# M3351 register map
File version: 1.0
Registers are 32-bit, read-write, reset 0x0 unless marked. A register's access mark holds for its fields unless they carry their own. Offsets are from the block's base; [hi:lo] are bit positions; {n}, {i} and the like mark numbered series; 'fields as' and 'values as' point back to an identical list.

## CLK (part 1 of 2) — CLK Register Map
Base 0x40000200
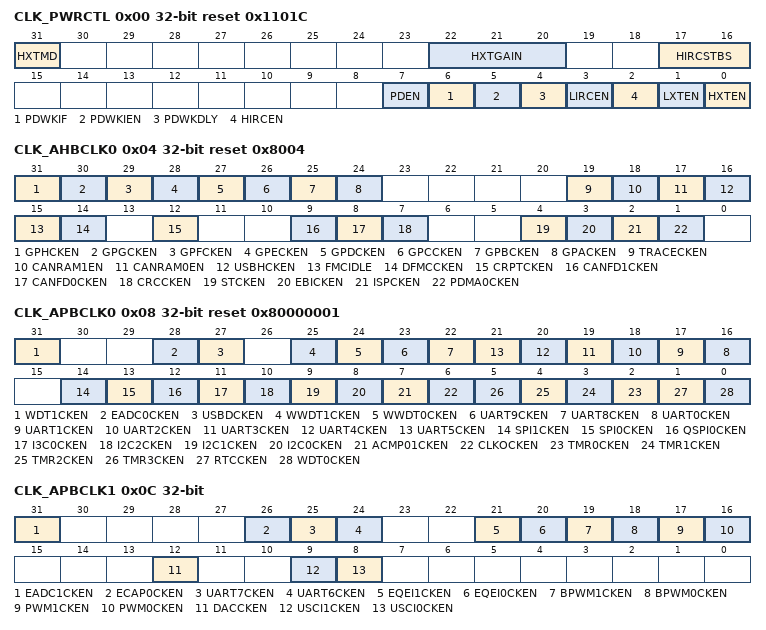
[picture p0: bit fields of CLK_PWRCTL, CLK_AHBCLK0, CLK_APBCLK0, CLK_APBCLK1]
0x00 CLK_PWRCTL reset 0x1101C (reset mask 0xFF0FFFFF) — System Power-down Control Register
  [31] HXTMD — HXT Mode Selection (Write Protect). Note: This bit is write protected. Refer to the SYS_REGCTL register.
    0=HXT work as crystal mode. PF.2 and PF.3 are configured as external high speed crystal (HXT) pins; 1=HXT works as external clock mode. PF.3 is configured as external clock input pin
  [22:20] HXTGAIN — HXT Gain Control Bit (Write Protect). Gain control is used to enlarge the gain of crystal to make sure crystal work normally. If gain control is enabled, crystal will consume more power than gain control off. Note: These bits are write protected. Refer to the SYS_REGLCTL register.
    0=HXT frequency is from 1 MHz to 4 MHz. (ESR=45ohm ; CLFXT =12.5pF); 1=HXT frequency is from 4 MHz to 8 MHz. (ESR=15ohm ; CLFXT =12.5pF); 2=HXT frequency is from 8 MHz to 12 MHz. (ESR=10ohm ; CLFXT =12.5pF); 3=HXT frequency is from 12 MHz to 16 MHz. (ESR=8.8ohm ; CLFXT =12.5pF); 4=HXT frequency is from 16 MHz to 24 MHz. (ESR=7.5ohm ; CLFXT =12.5pF); 5=HXT frequency is from 24 MHz to 32 MHz. (ESR=7.5ohm ; CLFXT =12.5pF)
  [17:16] HIRCSTBS — HIRC Stable Count Select (Write Protect). Note: These bits are write protected. Refer to the SYS_REGLCTL register.
    0=HIRC stable count is 1024 clocks; 1=HIRC stable count is 512 clocks
  [7] PDEN — System Power-down Enable (Write Protect). When this bit is set to 1, Power-down mode is enabled and chip keeps active till the CPU sleep mode is also active and then the chip enters Power-down mode. When chip wakes up from Power-down mode, this bit is auto cleared. Users need to set this bit again for next Power-down. In Power-down mode, HXT and the HIRC will be disabled in this mode, but LXT and LIRC are not controlled by Power-down mode. In Power-down mode, the PLL and system clock are disabled, and ignored the clock source selection. The clocks of peripheral are not controlled by Power-down mode, if the peripheral clock source is from LXT or LIRC. Note 1: This bit is write protected. Refer to the SYS_REGLCTL register. Note 2: System tick interrupt TICKINT(SYS_CTRL[1]) has to be disabled before entering to Power-down mode, to avoid system tick interrupt may influence system not entering power-down mode and keep operation.
    0=Chip will not enter Power-down mode after CPU sleep command WFI; 1=Chip enters Power-down mode after CPU sleep command WFI
  [6] PDWKIF — Power-down Mode Wake-up Interrupt Status. Set by 'Power-down wake-up event', it indicates that resume from Power-down mode. The flag is set if any wake-up source occurred. Refer Power Modes and Wake-up Sources chapter. Note 1: Write 1 to clear the bit to 0. Note 2: This bit works only if PDWKIEN (CLK_PWRCTL[5]) set to 1.
  [5] PDWKIEN — Power-down Mode Wake-up Interrupt Enable Bit (Write Protect). Note 1: The interrupt will occur when both PDWKIF and PDWKIEN are high. Note 2: This bit is write protected. Refer to the SYS_REGLCTL register.
    0=Power-down mode wake-up interrupt Disabled; 1=Power-down mode wake-up interrupt Enabled
  [4] PDWKDLY — Enable the Wake-up Delay Counter (Write Protect). When the chip wakes up from Power-down mode, the clock control will delay certain clock cycles to wait system clock stable. The delayed clock cycle is 1024 clock cycles when chip works using HXT, and 256 or 128 clock cycles when chip works using HIRC. Note: This bit is write protected. Refer to the SYS_REGLCTL register.
    0=Clock cycles delay Disabled; 1=Clock cycles delay Enabled
  [3] LIRCEN — LIRC Enable Bit (Write Protect). Note: This bit is write protected. Refer to the SYS_REGLCTL register.
    0=LIRC Disabled; 1=LIRC Enabled
  [2] HIRCEN — HIRC Enable Bit (Write Protect). Note 1: This bit is write protected. Refer to the SYS_REGLCTL register. Note 2: HIRC cannot be disabled and HIRCEN will read as 1 if HCLK clock source is selected from HIRC or PLL (clock source from HIRC).
    0=HIRC Disabled; 1=HIRC Enabled
  [1] LXTEN — LXT Enable Bit (Write Protect). Note: This bit is write protected. Refer to the SYS_REGLCTL register.
    0=LXT Disabled; 1=LXT Enabled
  [0] HXTEN — HXT Enable Bit (Write Protect). Note 1: This bit is write protected. Refer to the SYS_REGLCTL register. Note 2: HXT cannot be disabled and HXTEN will read as 1 if HCLK clock source is selected from HXT or PLL (clock source from HXT).
    0=HXT Disabled; 1=HXT Enabled
0x04 CLK_AHBCLK0 reset 0x8004 — AHB Devices Clock Enable Control Register 0
  [31] GPHCKEN — GPIOH Clock Enable Bit
    0=GPIOH clock Disabled; 1=GPIOH clock Enabled
  [30] GPGCKEN — GPIOG Clock Enable Bit
    0=GPIOG clock Disabled; 1=GPIOG clock Enabled
  [29] GPFCKEN — GPIOF Clock Enable Bit
    0=GPIOF clock Disabled; 1=GPIOF clock Enabled
  [28] GPECKEN — GPIOE Clock Enable Bit
    0=GPIOE clock Disabled; 1=GPIOE clock Enabled
  [27] GPDCKEN — GPIOD Clock Enable Bit
    0=GPIOD clock Disabled; 1=GPIOD clock Enabled
  [26] GPCCKEN — GPIOC Clock Enable Bit
    0=GPIOC clock Disabled; 1=GPIOC clock Enabled
  [25] GPBCKEN — GPIOB Clock Enable Bit
    0=GPIOB clock Disabled; 1=GPIOB clock Enabled
  [24] GPACKEN — GPIOA Clock Enable Bit
    0=GPIOA clock Disabled; 1=GPIOA clock Enabled
  [19] TRACECKEN — TRACE Clock Enable Bit
    0=TRACE clock Disabled; 1=TRACE clock Enabled
  [18] CANRAM1EN — CANFD1 Message SRAM Clock Enable Bit
    0=CANFD1 Message SRAM clock Disabled; 1=CANFD1 Message SRAM clock Enabled
  [17] CANRAM0EN — CANFD0 Message SRAM Clock Enable Bit
    0=CANFD0 Message SRAM clock Disabled; 1=CANFD0 Message SRAM clock Enabled
  [16] USBHCKEN — USB HOST Controller Clock Enable Bit
    0=USB HOST peripheral clock Disabled; 1=USB HOST peripheral clock Enabled
  [15] FMCIDLE — Flash Memory Controller Clock Enable Bit in IDLE Mode
    0=FMC clock Disabled when chip is under IDLE mode; 1=FMC clock Enabled when chip is under IDLE mode
  [14] DFMCCKEN — DFMC Clock Enable Bit
    0=DFMC clock Disabled; 1=DFMC clock Enabled
  [12] CRPTCKEN — Cryptographic Accelerator Clock Enable Bit
    0=Cryptographic Accelerator clock Disabled; 1=Cryptographic Accelerator clock Enabled
  [9] CANFD1CKEN — CANFD1 Clock Enable Bit
    0=CANFD1 clock Disabled; 1=CANFD1 clock Enabled
  [8] CANFD0CKEN — CANFD0 Clock Enable Bit
    0=CANFD0 clock Disabled; 1=CANFD0 clock Enabled
  [7] CRCCKEN — CRC Generator Controller Clock Enable Bit
    0=CRC peripheral clock Disabled; 1=CRC peripheral clock Enabled
  [4] STCKEN — System Tick Clock Enable Bit
    0=System tick clock Disabled; 1=System tick clock Enabled
  [3] EBICKEN — EBI Controller Clock Enable Bit
    0=EBI peripheral clock Disabled; 1=EBI peripheral clock Enabled
  [2] ISPCKEN — Flash ISP Controller Clock Enable Bit
    0=Flash ISP peripheral clock Disabled; 1=Flash ISP peripheral clock Enabled
  [1] PDMA0CKEN — PDMA0 Controller Clock Enable Bit
    0=PDMA0 peripheral clock Disabled; 1=PDMA0 peripheral clock Enabled
0x08 CLK_APBCLK0 reset 0x80000001 — APB Devices Clock Enable Control Register 0
  [31] WDT1CKEN — Watchdog Timer 1 Clock Enable Bit (Write Protect). Note: This bit is write protected. Refer to the SYS_REGLCTL register.
    0=Watchdog timer 1 clock Disabled; 1=Watchdog timer 1 clock Enabled
  [28] EADC0CKEN — EADC0 Clock Enable Bit
    0=EADC0 clock Disabled; 1=EADC0 clock Enabled
  [27] USBDCKEN — USB Device Clock Enable Bit
    0=USB device clock Disabled; 1=USB device clock Enabled
  [25] WWDT1CKEN — Window Watchdog Timer 1 Clock Enable Bit (Write Protect). Note: This bit is write protected. Refer to the SYS_REGLCTL register.
    0=Window Watchdog timer 1 clock Disabled; 1=Window Watchdog timer 1 clock Enabled
  [24] WWDT0CKEN — Window Watchdog Timer 0 Clock Enable Bit (Write Protect). Note: This bit is write protected. Refer to the SYS_REGLCTL register.
    0=Window Watchdog timer 0 clock Disabled; 1=Window Watchdog timer 0 clock Enabled
  [23] UART9CKEN — UART9 Clock Enable Bit
    0=UART9 clock Disabled; 1=UART9 clock Enabled
  [22] UART8CKEN — UART8 Clock Enable Bit
    0=UART8 clock Disabled; 1=UART8 clock Enabled
  [n+16] UART{n}CKEN (n=0..5) — UART{n} Clock Enable Bit
    0=UART{n} clock Disabled; 1=UART{n} clock Enabled
  [14] SPI1CKEN — SPI1 Clock Enable Bit
    0=SPI1 clock Disabled; 1=SPI1 clock Enabled
  [13] SPI0CKEN — SPI0 Clock Enable Bit
    0=SPI0 clock Disabled; 1=SPI0 clock Enabled
  [12] QSPI0CKEN — QSPI0 Clock Enable Bit
    0=QSPI0 clock Disabled; 1=QSPI0 clock Enabled
  [11] I3C0CKEN — I3C0 Clock Enable Bit
    0=I3C0 clock Disabled; 1=I3C0 clock Enabled
  [10] I2C2CKEN — I2C2 Clock Enable Bit
    0=I2C2 clock Disabled; 1=I2C2 clock Enabled
  [9] I2C1CKEN — I2C1 Clock Enable Bit
    0=I2C1 clock Disabled; 1=I2C1 clock Enabled
  [8] I2C0CKEN — I2C0 Clock Enable Bit
    0=I2C0 clock Disabled; 1=I2C0 clock Enabled
  [7] ACMP01CKEN — Analog Comparator 0/1 Clock Enable Bit
    0=Analog comparator 0/1 clock Disabled; 1=Analog comparator 0/1 clock Enabled
  [6] CLKOCKEN — CLKO Clock Enable Bit
    0=CLKO clock Disabled; 1=CLKO clock Enabled
  [n+2] TMR{n}CKEN (n=0..3) — Timer{n} Clock Enable Bit
    0=Timer{n} clock Disabled; 1=Timer{n} clock Enabled
  [1] RTCCKEN — Real-time-clock APB Interface Clock Enable Bit. This bit is used to control the RTC APB clock only. The RTC peripheral clock source is selected from RTCCKSEL(RTC_LXTCTL[7]). It can be selected to LXT or LIRC.
    0=RTC clock Disabled; 1=RTC clock Enabled
  [0] WDT0CKEN — Watchdog Timer 0 Clock Enable Bit (Write Protect). Note: This bit is write protected. Refer to the SYS_REGLCTL register.
    0=Watchdog timer 0 clock Disabled; 1=Watchdog timer 0 clock Enabled
0x0C CLK_APBCLK1 — APB Devices Clock Enable Control Register 1
  [31] EADC1CKEN — EADC1 Clock Enable Bit
    0=EADC1 clock Disabled; 1=EADC1 clock Enabled
  [26] ECAP0CKEN — ECAP0 Clock Enable Bit
    0=ECAP0 clock Disabled; 1=ECAP0 clock Enabled
  [25] UART7CKEN — UART7 Clock Enable Bit
    0=UART7 clock Disabled; 1=UART7 clock Enabled
  [24] UART6CKEN — UART6 Clock Enable Bit
    0=UART6 clock Disabled; 1=UART6 clock Enabled
  [21] EQEI1CKEN — EQEI1 Clock Enable Bit
    0=EQEI1 clock Disabled; 1=EQEI1 clock Enabled
  [20] EQEI0CKEN — EQEI0 Clock Enable Bit
    0=EQEI0 clock Disabled; 1=EQEI0 clock Enabled
  [19] BPWM1CKEN — BPWM1 Clock Enable Bit
    0=BPWM1 clock Disabled; 1=BPWM1 clock Enabled
  [18] BPWM0CKEN — BPWM0 Clock Enable Bit
    0=BPWM0 clock Disabled; 1=BPWM0 clock Enabled
  [17] PWM1CKEN — PWM1 Clock Enable Bit
    0=PWM1 clock Disabled; 1=PWM1 clock Enabled
  [16] PWM0CKEN — PWM0 Clock Enable Bit
    0=PWM0 clock Disabled; 1=PWM0 clock Enabled
  [12] DACCKEN — DAC Clock Enable Bit
    0=DAC clock Disabled; 1=DAC clock Enabled
  [9] USCI1CKEN — USCI1 Clock Enable Bit
    0=USCI1 clock Disabled; 1=USCI1 clock Enabled
  [8] USCI0CKEN — USCI0 Clock Enable Bit
    0=USCI0 clock Disabled; 1=USCI0 clock Enabled
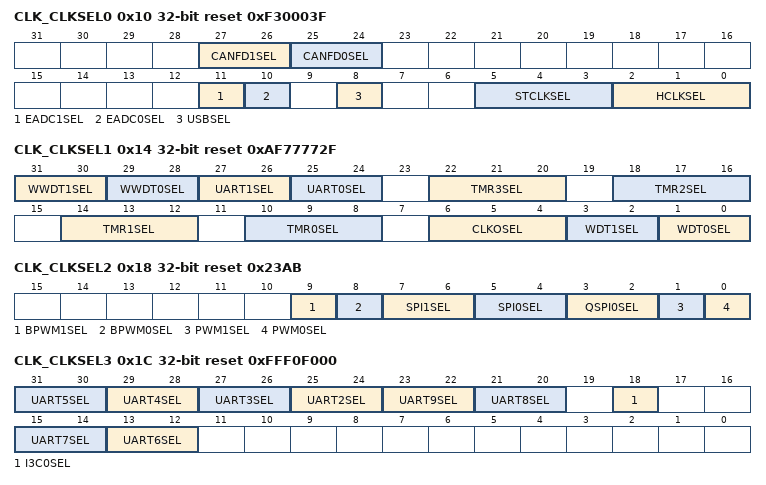
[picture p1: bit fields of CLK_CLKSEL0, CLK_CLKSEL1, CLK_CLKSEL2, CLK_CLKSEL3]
0x10 CLK_CLKSEL0 reset 0xF30003F — Clock Source Select Control Register 0
  [27:26] CANFD1SEL — CANFD1 Clock Source Selection (Write Protect). Note: These bits are write protected. Refer to the SYS_REGLCTL register.
    0=Clock source from HXT; 1=Clock source from PLL; 2=Clock source from HCLK; 3=Clock source from HIRC
  [25:24] CANFD0SEL — CANFD0 Clock Source Selection (Write Protect). Note: These bits are write protected. Refer to the SYS_REGLCTL register.
    values as CANFD1SEL
  [11] EADC1SEL — EADC1 Clock Source Selection (Write Protect). Note: These bits are write protected. Refer to the SYS_REGLCTL register.
    0=Clock source from HCLK; 1=Clock source from PLL
  [10] EADC0SEL — EADC0 Clock Source Selection (Write Protect). Note: These bits are write protected. Refer to the SYS_REGLCTL register.
    0=Clock source from HCLK; 1=Clock source from PLL
  [8] USBSEL — USB Clock Source Selection (Write Protect). Note: This bit is write protected. Refer to the SYS_REGLCTL register.
    0=Clock source from HIRC; 1=Clock source from PLL
  [5:3] STCLKSEL — Cortex-M33 SysTick Clock Source Selection (Write Protect). Note 2: These bits are write protected. Refer to the SYS_REGLCTL register.
    0=Clock source from HXT; 1=Clock source from LXT; 2=Clock source from HXT/2; 3=Clock source from HCLK/2; 7=Clock source from HIRC/2
  [2:0] HCLKSEL — HCLK Clock Source Selection (Write Protect). Before clock switching, the related clock sources (both pre-select and new-select) must be turned on. Note: Theses bits are write protected. Refer to the SYS_REGLCTL register.
    0=Clock source from HXT; 1=Clock source from LXT; 2=Clock source from PLL; 3=Clock source from LIRC; 7=Clock source from HIRC
0x14 CLK_CLKSEL1 reset 0xAF77772F — Clock Source Select Control Register 1
  [31:30] WWDT1SEL — Window Watchdog Timer 1 Clock Source Selection (Write Protect). Note: These bits are write protected. Refer to the SYS_REGLCTL register.
    2=Clock source from HCLK/2048; 3=Clock source from LIRC
  [29:28] WWDT0SEL — Window Watchdog Timer 0 Clock Source Selection (Write Protect). Note: These bits are write protected. Refer to the SYS_REGLCTL register.
    2=Clock source from HCLK/2048; 3=Clock source from LIRC
  [27:26] UART1SEL — UART1 Clock Source Selection
    0=Clock source from HXT; 1=Clock source from PLL; 2=Clock source from LXT; 3=Clock source from HIRC
  [25:24] UART0SEL — UART0 Clock Source Selection
    values as UART1SEL
  [22:20] TMR3SEL — TIMER3 Clock Source Selection
    0=Clock source from HXT; 1=Clock source from LXT; 2=Clock source from PCLK1; 3=Clock source from external clock TM3 pin; 5=Clock source from LIRC; 7=Clock source from HIRC
  [18:16] TMR2SEL — TIMER2 Clock Source Selection
    0=Clock source from HXT; 1=Clock source from LXT; 2=Clock source from PCLK1; 3=Clock source from external clock TM2 pin; 5=Clock source from LIRC; 7=Clock source from HIRC
  [14:12] TMR1SEL — TIMER1 Clock Source Selection
    0=Clock source from HXT; 1=Clock source from LXT; 2=Clock source from PCLK0; 3=Clock source from external clock TM1 pin; 5=Clock source from LIRC; 7=Clock source from HIRC
  [10:8] TMR0SEL — TIMER0 Clock Source Selection
    0=Clock source from HXT; 1=Clock source from LXT; 2=Clock source from PCLK0; 3=Clock source from external clock TM0 pin; 5=Clock source from LIRC; 7=Clock source from HIRC
  [6:4] CLKOSEL — Clock Output Clock Source Selection (Write Protect). Note: These bits are write protected. Refer to the SYS_REGLCTL register.
    0=Clock source from HXT; 1=Clock source from LXT; 2=Clock source from HCLK; 3=Clock source from HIRC; 4=Clock source from LIRC; 5=Clock source from PLL
  [3:2] WDT1SEL — Watchdog Timer 1 Clock Source Selection (Write Protect). Note: These bits are write protected. Refer to the SYS_REGLCTL register.
    1=Clock source from LXT; 2=Clock source from HCLK/2048; 3=Clock source from LIRC
  [1:0] WDT0SEL — Watchdog Timer 0 Clock Source Selection (Write Protect). Note: These bits are write protected. Refer to the SYS_REGLCTL register.
    values as WDT1SEL
0x18 CLK_CLKSEL2 reset 0x23AB — Clock Source Select Control Register 2
  [9] BPWM1SEL — BPWM1 Clock Source Selection. The peripheral clock source of BPWM1 is defined by BPWM1SEL.
    0=Clock source from HCLK; 1=Clock source from PCLK1
  [8] BPWM0SEL — BPWM0 Clock Source Selection. The peripheral clock source of BPWM0 is defined by BPWM0SEL.
    0=Clock source from HCLK; 1=Clock source from PCLK0
  [7:6] SPI1SEL — SPI1 Clock Source Selection
    0=Clock source from HXT; 1=Clock source from PLL; 2=Clock source from PCLK0; 3=Clock source from HIRC
  [5:4] SPI0SEL — SPI0 Clock Source Selection
    0=Clock source from HXT; 1=Clock source from PLL; 2=Clock source from PCLK1; 3=Clock source from HIRC
  [3:2] QSPI0SEL — QSPI0 Clock Source Selection
    values as SPI1SEL
  [1] PWM1SEL — PWM1 Clock Source Selection. The peripheral clock source of PWM1 is defined by PWM1SEL.
    0=Clock source from HCLK; 1=Clock source from PCLK1
  [0] PWM0SEL — PWM0 Clock Source Selection. The peripheral clock source of PWM0 is defined by PWM0SEL.
    0=Clock source from HCLK; 1=Clock source from PCLK0
0x1C CLK_CLKSEL3 reset 0xFFF0F000 — Clock Source Select Control Register 3
  [2n+21:2n+20] UART{n}SEL (n=2..5) — UART{n} Clock Source Selection
    values as CLK_CLKSEL1.UART1SEL
  [23:22] UART9SEL — UART9 Clock Source Selection
    values as CLK_CLKSEL1.UART1SEL
  [21:20] UART8SEL — UART8 Clock Source Selection
    values as CLK_CLKSEL1.UART1SEL
  [18] I3C0SEL — I3C0 Clock Source Selection
    0=Clock source from HCLK; 1=Clock source from PLL
  [15:14] UART7SEL — UART7 Clock Source Selection
    values as CLK_CLKSEL1.UART1SEL
  [13:12] UART6SEL — UART6 Clock Source Selection
    values as CLK_CLKSEL1.UART1SEL
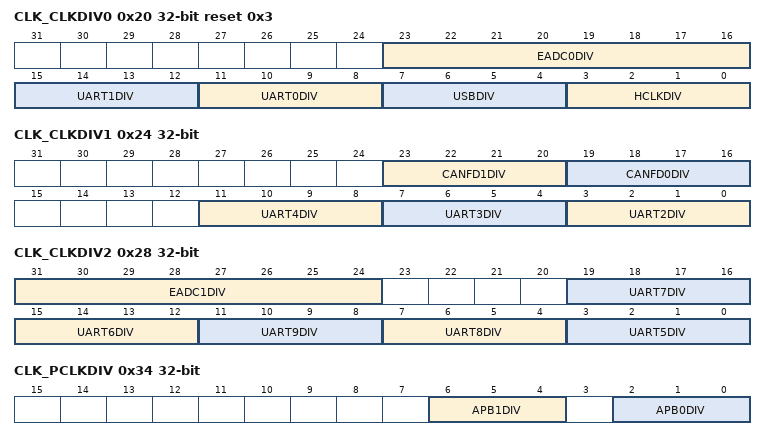
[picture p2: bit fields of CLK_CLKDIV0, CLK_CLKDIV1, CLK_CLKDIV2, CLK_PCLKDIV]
0x20 CLK_CLKDIV0 reset 0x3 — Clock Divider Number Register 0
  [23:16] EADC0DIV — EADC0 Clock Divide Number from EADC0 Clock Source
  [15:12] UART1DIV — UART1 Clock Divide Number from UART1 Clock Source
  [11:8] UART0DIV — UART0 Clock Divide Number from UART0 Clock Source
  [7:4] USBDIV — USB Clock Divide Number from USB Clock Source
  [3:0] HCLKDIV — HCLK Clock Divide Number from HCLK Clock Source
0x24 CLK_CLKDIV1 — Clock Divider Number Register 1
  [23:20] CANFD1DIV — CANFD1 Clock Divide Number from CANFD1 Clock Source
  [19:16] CANFD0DIV — CANFD0 Clock Divide Number from CANFD0 Clock Source
  [11:8] UART4DIV — UART4 Clock Divide Number from UART4 Clock Source
  [7:4] UART3DIV — UART3 Clock Divide Number from UART3 Clock Source
  [3:0] UART2DIV — UART2 Clock Divide Number from UART2 Clock Source
0x28 CLK_CLKDIV2 — Clock Divider Number Register 2
  [31:24] EADC1DIV — EADC1 Clock Divide Number from EADC1 Clock Source
  [19:16] UART7DIV — UART7 Clock Divide Number from UART7 Clock Source
  [15:12] UART6DIV — UART6 Clock Divide Number from UART6 Clock Source
  [11:8] UART9DIV — UART9 Clock Divide Number from UART9 Clock Source
  [7:4] UART8DIV — UART8 Clock Divide Number from UART8 Clock Source
  [3:0] UART5DIV — UART5 Clock Divide Number from UART5 Clock Source
0x34 CLK_PCLKDIV — APB Clock Divider Register
  [6:4] APB1DIV — APB1 Clock Divider. APB1 clock can be divided from HCLK.
    0=PCLK1 frequency is HCLK; 1=PCLK1 frequency is HCLK/2; 2=PCLK1 frequency is HCLK/4; 3=PCLK1 frequency is HCLK/8; 4=PCLK1 frequency is HCLK/16
  [2:0] APB0DIV — APB0 Clock Divider. APB0 clock can be divided from HCLK.
    0=PCLK0 frequency is HCLK; 1=PCLK0 frequency is HCLK/2; 2=PCLK0 frequency is HCLK/4; 3=PCLK0 frequency is HCLK/8; 4=PCLK0 frequency is HCLK/16
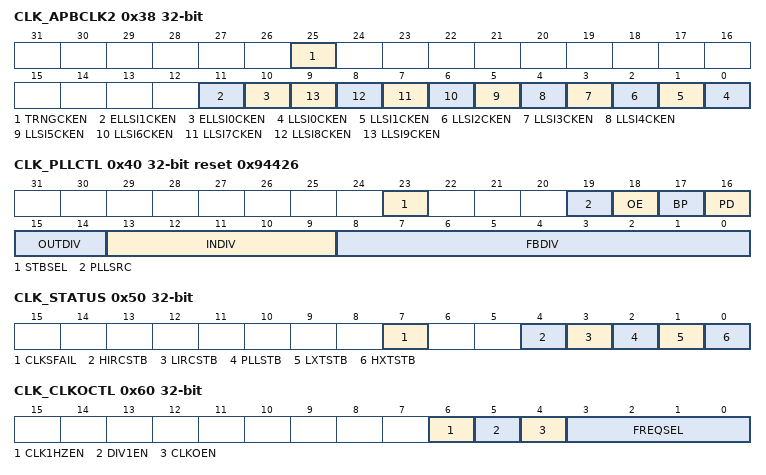
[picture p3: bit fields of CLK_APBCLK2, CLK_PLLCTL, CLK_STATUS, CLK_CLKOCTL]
0x38 CLK_APBCLK2 — APB Devices Clock Enable Control Register 2
  [25] TRNGCKEN — TRNG Clock Enable
    0=TRNG clock Disable; 1=TRNG clock Enable
  [11] ELLSI1CKEN — ELLSI1 Clock Enable Bit
    0=ELLSI1 clock Disabled; 1=ELLSI1 clock Enabled
  [10] ELLSI0CKEN — ELLSI0 Clock Enable Bit
    0=ELLSI0 clock Disabled; 1=ELLSI0 clock Enabled
  [n] LLSI{n}CKEN (n=0..9) — LLSI{n} Clock Enable Bit
    0=LLSI{n} clock Disabled; 1=LLSI{n} clock Enabled
0x40 CLK_PLLCTL reset 0x94426 — PLL Control Register
  [23] STBSEL — PLL Stable Counter Selection (Write Protect). Note: This bit is write protected. Refer to the SYS_REGLCTL register.
    0=PLL stable time is 2400 PLL source clock (suitable for source clock equal to or less than 12 MHz); 1=PLL stable time is 6400 PLL source clock (suitable for source clock larger than 12 MHz)
  [19] PLLSRC — PLL Source Clock Selection (Write Protect). Note: This bit is write protected. Refer to the SYS_REGLCTL register.
    0=PLL source clock from HXT; 1=PLL source clock from HIRC/4
  [18] OE — PLL FOUT Enable Control (Write Protect). Note: This bit is write protected. Refer to the SYS_REGLCTL register.
    0=PLL FOUT Enabled; 1=PLL FOUT is fixed low
  [17] BP — PLL Bypass Control (Write Protect). Note: This bit is write protected. Refer to the SYS_REGLCTL register.
    0=PLL is in normal mode (default); 1=PLL clock output is same as PLL input clock FIN
  [16] PD — Power-down Mode (Write Protect). If set the PDEN bit to 1 in CLK_PWRCTL register, the PLL will enter Power-down mode, too. Note 1: This bit is write protected. Refer to the SYS_REGLCTL register. Note 2: PLL cannot be disabled and PD will read as 1 if HCLK clock source is selected from PLL.
    0=PLL is in normal mode; 1=PLL is in Power-down mode (default)
  [15:14] OUTDIV — PLL Output Divider Control (Write Protect). Refer to the formulas below the table. Note: These bits are write protected. Refer to the SYS_REGLCTL register.
  [13:9] INDIV — PLL Input Divider Control (Write Protect). Refer to the formulas below the table. Note: These bits are write protected. Refer to the SYS_REGLCTL register.
  [8:0] FBDIV — PLL Feedback Divider Control (Write Protect). Refer to the formulas below the table. Note: These bits are write protected. Refer to the SYS_REGLCTL register.
0x50 CLK_STATUS ro (reset mask 0xFFFFF000) — Clock Status Monitor Register
  [7] CLKSFAIL — Clock Switching Fail Flag (Read Only). This bit is updated when software switches system clock source. If switch target clock is stable, this bit will be set to 0. If switch target clock is not stable, this bit will be set to 1. Note: This bit is read only. After selected clock source is stable, hardware will switch system clock to selected clock automatically, and CLKSFAIL will be cleared automatically by hardware.
    0=Clock switching success; 1=Clock switching failure
  [4] HIRCSTB — HIRC Clock Source Stable Flag (Read Only)
    0=48 MHz internal high speed RC oscillator (HIRC) clock is not stable or disabled; 1=48 MHz internal high speed RC oscillator (HIRC) clock is stable and enabled
  [3] LIRCSTB — LIRC Clock Source Stable Flag (Read Only)
    0=38.4 kHz internal low speed RC oscillator (LIRC) clock is not stable or disabled; 1=38.4 kHz internal low speed RC oscillator (LIRC) clock is stable and enabled
  [2] PLLSTB — Internal PLL Clock Source Stable Flag (Read Only)
    0=Internal PLL clock is not stable or disabled; 1=Internal PLL clock is stable and enabled
  [1] LXTSTB — LXT Clock Source Stable Flag (Read Only)
    0=32.768 kHz external low speed crystal oscillator (LXT) clock is not stable or disabled; 1=32.768 kHz external low speed crystal oscillator (LXT) clock is stabled and enabled
  [0] HXTSTB — HXT Clock Source Stable Flag (Read Only)
    0=4~32 MHz external high speed crystal oscillator (HXT) clock is not stable or disabled; 1=4~32 MHz external high speed crystal oscillator (HXT) clock is stable and enabled
0x60 CLK_CLKOCTL — Clock Output Control Register
  [6] CLK1HZEN — Clock Output 1Hz Enable Bit
    0=1 Hz clock output for 32.768 kHz frequency compensation Disabled; 1=1 Hz clock output for 32.768 kHz frequency compensation Enabled
  [5] DIV1EN — Clock Output Divide One Enable Bit
    0=Clock Output will output clock with source frequency divided by FREQSEL; 1=Clock Output will output clock with source frequency
  [4] CLKOEN — Clock Output Enable Bit
    0=Clock Output function Disabled; 1=Clock Output function Enabled
  [3:0] FREQSEL — Clock Output Frequency Selection. The formula of output frequency is. Fin is the input clock frequency. Fout is the frequency of divider output clock. N is the 4-bit value of FREQSEL[3:0].
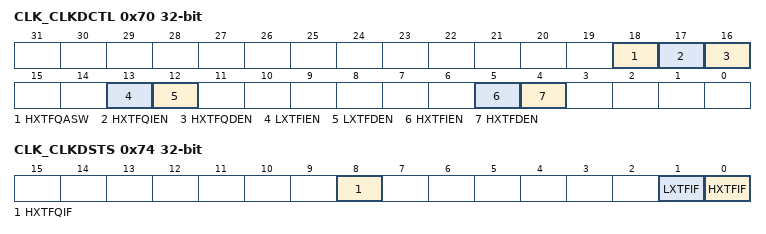
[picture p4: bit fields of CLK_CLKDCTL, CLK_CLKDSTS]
0x70 CLK_CLKDCTL — Clock Fail Detector Control Register
  [18] HXTFQASW — HXT Clock Frequency Range Detector Event Auto Switch Enable Bit. Note: This bit should be set before HXTFQDEN(CLK_CLKDCTL[16]).
    0=4~32 MHz external high speed crystal oscillator (HXT) clock frequency range detector fail event happened and HCLK will not switch to HIRC automatically; 1=4~32 MHz external high speed crystal oscillator (HXT) clock frequency range detector fail event happened and HCLK will switch to HIRC automatically
  [17] HXTFQIEN — HXT Clock Frequency Range Detector Interrupt Enable Bit
    0=4~32 MHz external high speed crystal oscillator (HXT) clock frequency range detector fail interrupt Disabled; 1=4~32 MHz external high speed crystal oscillator (HXT) clock frequency range detector fail interrupt Enabled
  [16] HXTFQDEN — HXT Clock Frequency Range Detector Enable Bit
    0=4~32 MHz external high speed crystal oscillator (HXT) clock frequency range detector Disabled; 1=4~32 MHz external high speed crystal oscillator (HXT) clock frequency range detector Enabled
  [13] LXTFIEN — LXT Clock Fail Interrupt Enable Bit
    0=32.768 kHz external low speed crystal oscillator (LXT) clock fail interrupt Disabled; 1=32.768 kHz external low speed crystal oscillator (LXT) clock fail interrupt Enabled
  [12] LXTFDEN — LXT Clock Fail Detector Enable Bit
    0=32.768 kHz external low speed crystal oscillator (LXT) clock fail detector Disabled; 1=32.768 kHz external low speed crystal oscillator (LXT) clock fail detector Enabled
  [5] HXTFIEN — HXT Clock Fail Interrupt Enable Bit
    0=4~32 MHz external high speed crystal oscillator (HXT) clock fail interrupt Disabled; 1=4~32 MHz external high speed crystal oscillator (HXT) clock fail interrupt Enabled
  [4] HXTFDEN — HXT Clock Fail Detector Enable Bit
    0=4~32 MHz external high speed crystal oscillator (HXT) clock fail detector Disabled; 1=4~32 MHz external high speed crystal oscillator (HXT) clock fail detector Enabled
0x74 CLK_CLKDSTS — Clock Fail Detector Status Register
  [8] HXTFQIF — HXT Clock Frequency Range Detector Interrupt Flag (Write Protect). Note 1: Write 1 to clear the bit to 0. Note 2: This bit is write protected. Refer to the SYS_REGLCTL register.
    0=4~32 MHz external high speed crystal oscillator (HXT) clock frequency is normal; 1=4~32 MHz external high speed crystal oscillator (HXT) clock frequency is abnormal
  [1] LXTFIF — LXT Clock Fail Interrupt Flag (Write Protect). Note 1: Write 1 to clear the bit to 0. Note 2: This bit is write protected. Refer to the SYS_REGLCTL register.
    0=32.768 kHz external low speed crystal oscillator (LXT) clock is normal; 1=32.768 kHz external low speed crystal oscillator (LXT) clock stops
  [0] HXTFIF — HXT Clock Fail Interrupt Flag (Write Protect). Note 1: Write 1 to clear the bit to 0. Note 2: This bit is write protected. Refer to the SYS_REGLCTL register.
    0=4~32 MHz external high speed crystal oscillator (HXT) clock is normal; 1=4~32 MHz external high speed crystal oscillator (HXT) clock stops
